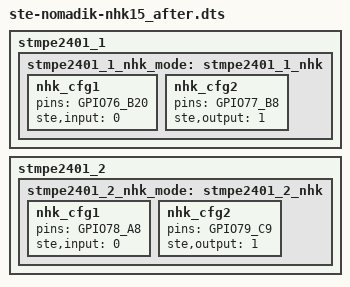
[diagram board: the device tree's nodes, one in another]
		stmpe2401_1 {
			stmpe2401_1_nhk_mode: stmpe2401_1_nhk {
				nhk_cfg1 {
					pins = "GPIO76_B20"; // IRQ line
					ste,input = <0>;
				};
				nhk_cfg2 {
					pins = "GPIO77_B8"; // reset line
					ste,output = <1>;
				};
			};
		};
		stmpe2401_2 {
			stmpe2401_2_nhk_mode: stmpe2401_2_nhk {
				nhk_cfg1 {
					pins = "GPIO78_A8"; // IRQ line
					ste,input = <0>;
				};
				nhk_cfg2 {
					pins = "GPIO79_C9"; // reset line
					ste,output = <1>;
				};
			};
		};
